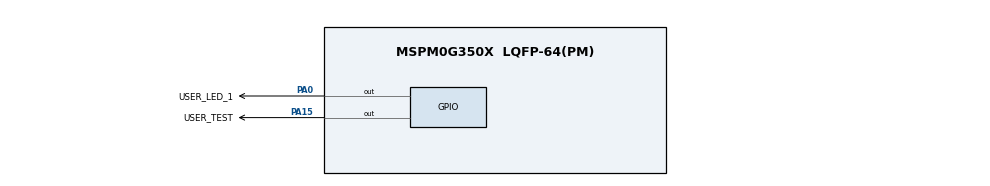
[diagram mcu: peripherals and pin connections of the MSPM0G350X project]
// @cliArgs --device "MSPM0G350X" --package "LQFP-64(PM)" --part "Default"
// @cliArgs --board /ti/boards/LP_MSPM0G3507 --rtos nortos

/**
 * Import the modules used in this configuration.
 */
const Board  = scripting.addModule("/ti/driverlib/Board");
const SYSCTL = scripting.addModule("/ti/driverlib/SYSCTL");
const GPIO  = scripting.addModule("/ti/driverlib/GPIO", {}, false);
const GPIO1 = GPIO.addInstance();

GPIO1.$name                                 = "GPIO_LEDS";
GPIO1.associatedPins.create(2);
GPIO1.associatedPins[0].$name               = "USER_LED_1";
GPIO1.associatedPins[0].initialValue        = "SET";
GPIO1.associatedPins[0].assignedPort        = "PORTA";
GPIO1.associatedPins[0].assignedPortSegment = "Lower";
GPIO1.associatedPins[0].pin.$assign         = "PA0";
GPIO1.associatedPins[1].$name               = "USER_TEST";
GPIO1.associatedPins[1].initialValue        = "SET";
GPIO1.associatedPins[1].assignedPort        = "PORTA";
GPIO1.associatedPins[1].assignedPortSegment = "Lower";
GPIO1.associatedPins[1].pin.$assign         = "PA15";

SYSCTL.forceDefaultClkConfig = true;
SYSCTL.clockTreeEn           = true;
